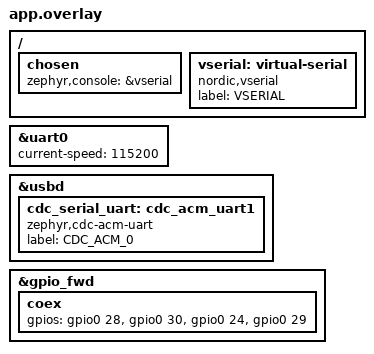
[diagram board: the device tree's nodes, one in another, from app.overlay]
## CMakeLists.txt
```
#
# Copyright (c) 2025 Mikko Jaakkola
#
# SPDX-License-Identifier: LicenseRef-Nordic-5-Clause
#

cmake_minimum_required(VERSION 3.20.5)
cmake_policy(SET CMP0057 NEW)

# Register the embedded80211 common link protocol library as an out-of-tree
# Zephyr module so its sources are compiled and linked into the image.
# Must be set before find_package(Zephyr) so the module is discovered during
# Zephyr's kernel-mode build configuration.
set(ZEPHYR_EXTRA_MODULES ${CMAKE_CURRENT_SOURCE_DIR}/../embedded80211)

# Rebalance the flash/SRAM partitions so the Wi-Fi co-processor appcore fits
# (see partitions.overlay.dts). Must be set before find_package(Zephyr): the
# variable is gathered during Zephyr package processing.
set(EXTRA_DTC_OVERLAY_FILE ${CMAKE_CURRENT_SOURCE_DIR}/partitions.overlay.dts)

find_package(Zephyr REQUIRED HINTS $ENV{ZEPHYR_BASE})

project(embedded80211_serial)

target_include_directories(app PUBLIC ${ZEPHYR_BASE}/subsys/net/ip)

target_sources(app PRIVATE
	src/main.c
)
```

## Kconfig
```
#
# Copyright (c) 2022 Nordic Semiconductor
#
# SPDX-License-Identifier: LicenseRef-Nordic-5-Clause
#

source "Kconfig.zephyr"
```

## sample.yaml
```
sample:
  description: Wi-Fi station sample application
  name: Wi-Fi station
tests:
  sample.nrf7002.sta:
    sysbuild: true
    build_only: true
    integration_platforms:
      - nrf7002dk/nrf5340/cpuapp
    platform_allow: nrf7002dk/nrf5340/cpuapp
    tags:
      - ci_build
      - sysbuild
      - ci_samples_wifi
  sample.nrf7002.sta.no_wifi_ready:
    sysbuild: true
    build_only: true
    extra_args: CONFIG_WIFI_READY_LIB=n
    integration_platforms:
      - nrf7002dk/nrf5340/cpuapp
    platform_allow: nrf7002dk/nrf5340/cpuapp
    tags:
      - ci_build
      - sysbuild
      - ci_samples_wifi
  sample.nrf7001.sta:
    sysbuild: true
    build_only: true
    integration_platforms:
      - nrf7002dk/nrf5340/cpuapp/nrf7001
    platform_allow: nrf7002dk/nrf5340/cpuapp/nrf7001
    tags:
      - ci_build
      - sysbuild
      - ci_samples_wifi
    skip: true
  sample.nrf7002_eks.sta:
    sysbuild: true
    build_only: true
    extra_args: SHIELD=nrf7002ek
    integration_platforms:
      - nrf5340dk/nrf5340/cpuapp
      - nrf52840dk/nrf52840
    platform_allow:
      - nrf5340dk/nrf5340/cpuapp
      - nrf52840dk/nrf52840
    extra_configs:
      - CONFIG_NET_TX_STACK_SIZE=3700
      - CONFIG_NET_RX_STACK_SIZE=3700
    tags:
      - ci_build
      - sysbuild
      - ci_samples_wifi
  sample.nrf7001_eks.sta:
    sysbuild: true
    build_only: true
    extra_args: SHIELD=nrf7002ek_nrf7001
    integration_platforms:
      - nrf5340dk/nrf5340/cpuapp
      - nrf52840dk/nrf52840
    platform_allow:
      - nrf5340dk/nrf5340/cpuapp
      - nrf52840dk/nrf52840
    extra_configs:
      - CONFIG_NET_TX_STACK_SIZE=3700
      - CONFIG_NET_RX_STACK_SIZE=3700
    tags:
      - ci_build
      - sysbuild
      - ci_samples_wifi
```

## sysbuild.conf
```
#
# Copyright (c) 2024 Nordic Semiconductor ASA
#
# SPDX-License-Identifier: LicenseRef-Nordic-5-Clause
#

SB_CONFIG_WIFI_NRF70=y

# Build the network core image (Nordic ipc_radio application) with the
# Bluetooth controller serialized to the application core over HCI IPC.
SB_CONFIG_NETCORE_IPC_RADIO_BT_HCI_IPC=y
```

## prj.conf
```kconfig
#
# Copyright (c) 2025 Mikko Jaakkola
#
#
CONFIG_WIFI=y
CONFIG_WIFI_NRF70=y

# WPA supplicant
CONFIG_WIFI_NM_WPA_SUPPLICANT=y
CONFIG_WIFI_READY_LIB=y
# Station-only, PSK/WPA2-CCMP: disable WPA3/SAE and legacy (WEP/TKIP/MD5/RC4)
# crypto to cut flash. This co-processor never uses SAE, WEP, or TKIP.
CONFIG_WIFI_NM_WPA_SUPPLICANT_WPA3_IMPLEMENTATION_EXT=n
CONFIG_WIFI_NM_WPA_SUPPLICANT_WPA3_IMPLEMENTATION_INT=n
CONFIG_WIFI_NM_WPA_SUPPLICANT_LEGACY_CRYPTO=n
CONFIG_WIFI_NM_WPA_SUPPLICANT_WEP=n
# Low power must be disabled for monitor-mode raw RX capture: with LPM the
# nRF7002 RPU puts the radio to sleep after ~10 ms idle, and in monitor mode
# there is no beacon/DTIM to wake it, so air frames are never captured.
# (Reference: nrf/tests/drivers/nrf_wifi/raw_tx_rx/prj.conf.)
# Note: this also disables CONFIG_NRF_WIFI_RPU_RECOVERY (depends on LPM).
CONFIG_NRF_WIFI_LOW_POWER=n
# Force a valid unicast station MAC. The default (CONFIG_WIFI_OTP_MAC_ADDRESS)
# makes nrf_wifi_get_mac_addr() write a dummy/garbage first octet with the
# multicast bit set (observed 03:06:f4:ce:36:00 on the bus); a DHCP server
# rejects DISCOVERs from such a source, so no OFFER ever returns. A fixed
# unicast MAC (bit0/bit1 of the first octet clear) fixes DHCP.
CONFIG_WIFI_FIXED_MAC_ADDRESS="62:34:56:78:9a:bc"

# Networking
CONFIG_NETWORKING=y
CONFIG_NET_SOCKETS=y
CONFIG_NET_IPV4=n
CONFIG_NET_UDP=n
CONFIG_NET_TCP=n
CONFIG_NET_DHCPV4=n

# Data proxy (co-processor) mode: the FMAC handles MAC filtering on the
# device MAC (00:00:00:00:00:00:01, which is also the host's MAC). Every L2
# frame the FMAC delivers is forwarded to the host over the bus via the
# nrf_wifi_if_rx_frm_hook (see wifi_data.c). Monitor/sniffer mode
# (PROMISC/RAW_DATA_RX) is NOT used here: it delivers every air frame
# (beacons, other clients) and breaks STA operation.
CONFIG_NRF70_RAW_DATA_TX=y
# Engineering: raw RX capture for broadcast-echo validation
CONFIG_WIFI_RAW_RX=y

CONFIG_NET_PKT_RX_COUNT=16
CONFIG_NET_PKT_TX_COUNT=8
CONFIG_NRF70_RX_NUM_BUFS=8

# Below section is the primary contributor to SRAM. Sized to fit the
# original 192 KB non-secure SRAM partition (was tuned for performance).
# Heap enlarged for wpa_supplicant (WPA state machine + EAPOL + ctrl iface
# need ~60 KB total; the 30 KB HEAP_MEM_POOL_ADD_SIZE_HOSTAP is added on
# top of HEAP_MEM_POOL_SIZE by the hostap module). Net bufs trimmed to
# compensate.
CONFIG_NET_BUF_RX_COUNT=8
CONFIG_NET_BUF_TX_COUNT=8
CONFIG_HEAP_MEM_POOL_SIZE=32000
CONFIG_HEAP_MEM_POOL_IGNORE_MIN=y
CONFIG_NRF_WIFI_CTRL_HEAP_SIZE=12000
CONFIG_NRF_WIFI_DATA_HEAP_SIZE=16000
CONFIG_NET_TC_TX_COUNT=1

#CONFIG_NET_IF_UNICAST_IPV4_ADDR_COUNT=1
CONFIG_NET_MAX_CONTEXTS=5
CONFIG_NET_CONTEXT_SYNC_RECV=y

CONFIG_INIT_STACKS=y

CONFIG_NET_L2_ETHERNET=y
CONFIG_NET_L2_ETHERNET_MGMT=y

CONFIG_NET_CONFIG_SETTINGS=y
CONFIG_NET_CONFIG_INIT_TIMEOUT=0

CONFIG_NET_SOCKETS_POLL_MAX=10

# Memories
CONFIG_MAIN_STACK_SIZE=5200
CONFIG_NET_TX_STACK_SIZE=4096
CONFIG_NET_RX_STACK_SIZE=4096
CONFIG_STA_SAMPLE_START_WIFI_THREAD_STACK_SIZE=5200

# Debugging
CONFIG_STACK_SENTINEL=y
# The FMAC RPC/RX path (incl. the embedded80211 RX hook) overflows the
# default RPMSG workqueue stack at boot when beacons are delivered.
CONFIG_IPC_SERVICE_BACKEND_RPMSG_WQ_STACK_SIZE=4096
# Main thread runs net_if / Wi-Fi init; 5200 bytes is fully consumed at boot.
CONFIG_MAIN_STACK_SIZE=6144
# The "wlan0" net-if management thread overflows at 4600 bytes during
# FMAC-init RPC handling; bump to 8192.
CONFIG_NET_MGMT_EVENT_STACK_SIZE=6144
CONFIG_SHELL_CMDS_RESIZE=n


# Kernel options
CONFIG_ENTROPY_GENERATOR=y

# Logging
CONFIG_LOG=y
CONFIG_LOG_BUFFER_SIZE=2048
# USB stack logging: WRN to keep boot log short so Wi-Fi connect logs fit
# in the 4 KB RTT ring (NO_BLOCK_SKIP drops everything once full).
CONFIG_USBD_LOG_LEVEL_WRN=y
CONFIG_UDC_DRIVER_LOG_LEVEL_WRN=y
CONFIG_USBD_CDC_ACM_LOG_LEVEL_WRN=y
# TEMP: connect-timeout diagnosis — WPA supplicant debug logs (level 1 = MSG_DEBUG).
# Remove once the -116 ETIMEDOUT root cause is found.
#CONFIG_WIFI_NM_WPA_SUPPLICANT_LOG_LEVEL_DBG=y
#CONFIG_WIFI_NM_WPA_SUPPLICANT_DEBUG_LEVEL=1
# Free flash for the debug logging above (not needed for basic STA connect).
#CONFIG_WIFI_NM_WPA_SUPPLICANT_ADVANCED_FEATURES=n

# Nanopb
CONFIG_NANOPB=y

# Bluetooth LE
# The controller is the nRF5340 on-chip SoftDevice Controller running on the
# network core (the ipc_radio netcore image, see Kconfig.sysbuild). The
# application core exposes a raw HCI channel to the host over the common
# link protocol (traffic type HCI, see src/bt_proxy.c).
CONFIG_BT=y
CONFIG_BT_HCI_RAW=y
CONFIG_MBOX=y
CONFIG_IPC_SERVICE=y

# Serial transport: the nRF5340 target USB connector (see app.overlay)
# exposes the common link protocol bus as USB CDC-ACM (CDC_ACM_0).
# The J-Link USB connector carries only SWD flash/debug and SEGGER RTT.

# Enable USB Subsystem (new USB device stack)
CONFIG_USB_DEVICE_STACK_NEXT=y
# The USB device controller (UDC NRF) thread handles CDC-ACM ISR events and
# overflows the default 512-byte stack at boot. Bump to 2048.
#CONFIG_UDC_NRF_THREAD_STACK_SIZE=4096

# Enable CDC ACM class for USB device stack next
CONFIG_USBD_CDC_ACM_CLASS=y

# Keep vserial for console, but don't proxy it to USB (prevents console
# output from corrupting the protocol data channel on CDC_ACM_0)
CONFIG_VSERIAL_ENABLE=y
CONFIG_SERIAL_MUX_VSERIAL_IFACE_UART=y
# Disable early console to prevent boot banner from corrupting CDC ACM data
CONFIG_EARLY_CONSOLE=n

# The USB device stack is initialized explicitly at boot by
# embedded80211/zephyr/device/serial/usbd_init.c (USBD_DEVICE_DEFINE +
# usbd_init()/usbd_enable()). It registers the first zephyr,cdc-acm-uart
# instance ("cdc_acm_0" = cdc_serial_uart, the multiplexer's USB backend
# bound by serial_usb.c). The VID/PID and descriptor strings are defined
# in usbd_init.c.

# Serial
CONFIG_SERIAL=y
 # Needed for USB CDC ACM. Aysynchronous serial port
# API would be better for all other serial ports.
CONFIG_UART_INTERRUPT_DRIVEN=y

# Enable RTT (Real-Time Transfer)
CONFIG_RTT_CONSOLE=y

# Choose SEGGER RTT as the backend (most common)
CONFIG_USE_SEGGER_RTT=y
CONFIG_SEGGER_RTT_BUFFER_SIZE_UP=4096
CONFIG_SEGGER_RTT_BUFFER_SIZE_DOWN=64
# Re-init the RTT control block unconditionally on every boot. The CB lives in
# a persistent section (not zeroed by startup), so the default strong-check
# mode reuses offsets left by the previous boot: the ring stays full of stale
# data and the skip-mode log writer drops everything new. Fresh ring per boot.
CONFIG_SEGGER_RTT_INIT_MODE_ALWAYS=y

# Workqueue.
CONFIG_SYSTEM_WORKQUEUE_STACK_SIZE=4096
CONFIG_SYSTEM_WORKQUEUE_PRIORITY=-1

# Enable events
CONFIG_EVENTS=y

# CRC32C for the link-protocol per-frame integrity feature (serial.c).
CONFIG_CRC=y
# The ARM MPU's default-deny background region blocks peripheral accesses
# (0x40000000+) that the SPU (configured by TF-M) is supposed to allow.
# The SPU handles all access control for the NS world; the ARM MPU is
# redundant and causes an MPU fault at boot when the NS image first
# touches a peripheral register.
CONFIG_ARM_MPU=n
```

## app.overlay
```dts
/*
 * Serial transport: the nRF5340 target USB connector (a second USB cable,
 * separate from the J-Link USB used for SWD flash/debug) exposes two USB
 * CDC-ACM ports (VID 0x2FE3):
 *
 *   CDC_ACM_0 (cdc_serial_uart):  common link protocol bus — the
 *                                 multiplexer's USB backend (serial_usb.c)
 *   CDC_ACM_1 (cdc_serial_uart2): spare port, not bound to a console
 *
 * The console is the vserial virtual UART (chosen below): by design the
 * Zephyr console has no physical pins, and console writes are dropped by
 * vserial's poll stub. Real logs flow over SEGGER RTT (SWD, J-Link cable).
 *
 * uart0 stays enabled as the multiplexer's UART backend (uart.c; default
 * CONFIG_SERIAL_MUX_IFACE_UART), but no protocol traffic is routed to it:
 * every traffic type defaults to the USB interface.
 */
&uart0 {
    status = "okay";
    current-speed = <115200>;
};

&usbd {
    cdc_serial_uart: cdc_acm_uart1 {
        compatible = "zephyr,cdc-acm-uart";
        label = "CDC_ACM_0";
    };
};
/* Forward the nRF7002 Wi-Fi PTA (coexistence) pins to the network core.
 * The network core drives them from the nrf_radio_coex node in its
 * devicetree (MPSL_CX_NRF700X), arbitrating RF access between the
 * nRF5340 Bluetooth radio and the nRF7002 Wi-Fi radio.
 */
&gpio_fwd {
    coex {
        gpios = <&gpio0 28 0>,  /* COEX_REQ */
                <&gpio0 30 0>,  /* COEX_STATUS0 */
                <&gpio0 24 0>,  /* COEX_GRANT */
                <&gpio0 29 0>;  /* SWCTRL1 */
    };
};

/ {
     chosen {
         /*
          * Console sink: the vserial virtual UART (no physical pins), by
          * design. Console writes are dropped by vserial's poll stub;
          * logs flow over SEGGER RTT (SWD, J-Link cable).
          */
         zephyr,console = &vserial;
     };

     vserial: virtual-serial {
         compatible = "nordic,vserial";
         status = "okay";
         label = "VSERIAL";
     };
};
```

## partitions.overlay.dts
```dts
/*
 * Copyright (c) 2025 Mikko Jaakkola
 *
 * SPDX-License-Identifier: LicenseRef-Nordic-5-Clause
 *
 * Project partition override for the nRF7002 DK non-secure appcore.
 *
 * The Wi-Fi co-processor appcore needs ~535 KB flash / ~201 KB SRAM, which
 * does not fit the default 192 KB non-secure partition (the nRF7002 radio
 * firmware + wpa_supplicant core alone are ~335 KB and are not trimmable).
 *
 * This overlay rebalances the 1 MB flash and 512 KB SRAM. This build has
 * BL2 disabled (BL2=FALSE), so the secure image is the first image and must
 * sit at 0x0 (the nRF5340 APP core always resets to 0x0). The default
 * mcuboot/BL2 partition at 0x0 is therefore removed and slot0 is moved to
 * 0x0:
 *
 *   Flash (1 MB):
 *     0x00000  slot0: S (128 KB) + NS (544 KB) = 672 KB
 *     0xA8000  free (was the 448 KB slot1 secondary; no in-place DFU here)
 *     0xF0000  PS (16 KB) / ITS (8 KB) / OTP (8 KB)
 *
 *   SRAM (512 KB):
 *     0x00000  sram0_s        (256 KB, secure)
 *     0x40000  sram0_ns_app   (208 KB)
 *     0x74000  sram0_shared   (48 KB, IPC)
 *
 * The NCS tfm_boards partition header derives the S/NS sizes from these DTS
 * nodes, so no upstream TF-M header is modified.
 */

&slot0_partition {
	reg = <0x00000000 0xA8000>;
	ranges = <0x0 0x0 0xA8000>;
};

&slot0_s_partition {
	reg = <0x00000000 0x20000>;
};

&slot0_ns_partition {
	reg = <0x00020000 0x88000>;
};

/* No BL2/MCUBoot in this build (BL2=FALSE): remove the 64 KB boot partition
 * at 0x0 so slot0 can start there. Also free the 448 KB secondary slot; this
 * build has no in-place DFU. */
&flash0 {
	partitions {
		/delete-node/ boot_partition;
		/delete-node/ slot1_partition;
	};
};

&sram0_ns_app {
	reg = <0x0 0x34000>;
};

&sram0_shared {
	reg = <0x74000 0xC000>;
};
```

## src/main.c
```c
/*
 * Copyright (c) 2022 Nordic Semiconductor ASA
 *
 * SPDX-License-Identifier: LicenseRef-Nordic-5-Clause
 */

/** @file
 * @brief WiFi station sample
 */

#include <zephyr/logging/log.h>
LOG_MODULE_REGISTER(embedded80211_serial, CONFIG_LOG_DEFAULT_LEVEL);

#include <zephyr/kernel.h>
#include <stdio.h>
#include <stdlib.h>
#include <zephyr/shell/shell.h>
#include <zephyr/sys/printk.h>
#include <zephyr/init.h>

#include <zephyr/net/net_if.h>
#include <zephyr/net/wifi_mgmt.h>
#include <zephyr/net/net_event.h>
#include <zephyr/drivers/gpio.h>

#ifdef CONFIG_WIFI_READY_LIB
#include <net/wifi_ready.h>
#endif /* CONFIG_WIFI_READY_LIB */

#if defined(CONFIG_BOARD_NRF7002DK_NRF7001_NRF5340_CPUAPP) || \
	defined(CONFIG_BOARD_NRF7002DK_NRF5340_CPUAPP)
#include <zephyr/drivers/wifi/nrf_wifi/bus/qspi_if.h>
#endif

#include "net_private.h"

#define WIFI_SHELL_MODULE "wifi"

#define WIFI_SHELL_MGMT_EVENTS (NET_EVENT_WIFI_CONNECT_RESULT |		\
				NET_EVENT_WIFI_DISCONNECT_RESULT)

#define MAX_SSID_LEN        32
#define STATUS_POLLING_MS   300

/* 1000 msec = 1 sec */
#define LED_SLEEP_TIME_MS   100

/* The devicetree node identifier for the "led0" alias. */
#define LED0_NODE DT_ALIAS(led0)
/*
 * A build error on this line means your board is unsupported.
 * See the sample documentation for information on how to fix this.
 */
static const struct gpio_dt_spec led = GPIO_DT_SPEC_GET(LED0_NODE, gpios);

static struct net_mgmt_event_callback wifi_shell_mgmt_cb;
static struct net_mgmt_event_callback net_shell_mgmt_cb;

#ifdef CONFIG_WIFI_READY_LIB
static K_SEM_DEFINE(wifi_ready_state_changed_sem, 0, 1);
static bool wifi_ready_status;
#endif /* CONFIG_WIFI_READY_LIB */

static struct {
	const struct shell *sh;
	union {
		struct {
			uint8_t connected	: 1;
			uint8_t connect_result	: 1;
			uint8_t disconnect_requested	: 1;
			uint8_t _unused		: 5;
		};
		uint8_t all;
	};
} context;

void toggle_led(void)
{
	int ret;

	if (!device_is_ready(led.port)) {
		LOG_ERR("LED device is not ready");
		return;
	}

	ret = gpio_pin_configure_dt(&led, GPIO_OUTPUT_ACTIVE);
	if (ret < 0) {
		LOG_ERR("Error %d: failed to configure LED pin", ret);
		return;
	}

	while (1) {
		if (context.connected) {
			gpio_pin_toggle_dt(&led);
			k_msleep(LED_SLEEP_TIME_MS);
		} else {
			gpio_pin_set_dt(&led, 0);
			k_msleep(LED_SLEEP_TIME_MS);
		}
	}
}

K_THREAD_DEFINE(led_thread_id, 1024, toggle_led, NULL, NULL, NULL,
		7, 0, 0);

static int cmd_wifi_status(void)
{
	struct net_if *iface = net_if_get_default();
	struct wifi_iface_status status = { 0 };

	if (net_mgmt(NET_REQUEST_WIFI_IFACE_STATUS, iface, &status,
				sizeof(struct wifi_iface_status))) {
		LOG_ERR("Status request failed");

		return -ENOEXEC;
	}

	/* The caller polls every STATUS_POLLING_MS; log only state changes so
	 * the log backend is not flooded with identical lines. */
	static bool have_last;
	static int last_state;

	if (have_last && status.state == last_state) {
		return 0;
	}
	have_last = true;
	last_state = status.state;

	LOG_INF("==================");
	LOG_INF("State: %s", wifi_state_txt(status.state));

	if (status.state >= WIFI_STATE_ASSOCIATED) {
		uint8_t mac_string_buf[sizeof("xx:xx:xx:xx:xx:xx")];

		LOG_INF("Interface Mode: %s",
		       wifi_mode_txt(status.iface_mode));
		LOG_INF("Link Mode: %s",
		       wifi_link_mode_txt(status.link_mode));
		LOG_INF("SSID: %.32s", status.ssid);
		LOG_INF("BSSID: %s",
		       net_sprint_ll_addr_buf(
				status.bssid, WIFI_MAC_ADDR_LEN,
				mac_string_buf, sizeof(mac_string_buf)));
		LOG_INF("Band: %s", wifi_band_txt(status.band));
		LOG_INF("Channel: %d", status.channel);
		LOG_INF("Security: %s", wifi_security_txt(status.security));
		LOG_INF("MFP: %s", wifi_mfp_txt(status.mfp));
		LOG_INF("RSSI: %d", status.rssi);
	}
	return 0;
}

static void handle_wifi_connect_result(struct net_mgmt_event_callback *cb)
{
	const struct wifi_status *status =
		(const struct wifi_status *) cb->info;

	if (context.connected) {
		return;
	}

	if (status->status) {
		LOG_ERR("Connection failed (%d)", status->status);
	} else {
		LOG_INF("Connected");
		context.connected = true;
	}

	context.connect_result = true;
}

static void handle_wifi_disconnect_result(struct net_mgmt_event_callback *cb)
{
	const struct wifi_status *status =
		(const struct wifi_status *) cb->info;

	if (!context.connected) {
		return;
	}

	if (context.disconnect_requested) {
		LOG_INF("Disconnection request %s (%d)",
			 status->status ? "failed" : "done",
					status->status);
		context.disconnect_requested = false;
	} else {
		LOG_INF("Received Disconnected");
		context.connected = false;
	}

	cmd_wifi_status();
}

static void wifi_mgmt_event_handler(struct net_mgmt_event_callback *cb,
				     uint64_t mgmt_event, struct net_if *iface)
{
	switch (mgmt_event) {
	case NET_EVENT_WIFI_CONNECT_RESULT:
		handle_wifi_connect_result(cb);
		break;
	case NET_EVENT_WIFI_DISCONNECT_RESULT:
		handle_wifi_disconnect_result(cb);
		break;
	default:
		break;
	}
}

static void net_mgmt_event_handler(struct net_mgmt_event_callback *cb,
				    uint64_t mgmt_event, struct net_if *iface)
{
	switch (mgmt_event) {
	case NET_EVENT_IPV4_DHCP_BOUND:
		//print_dhcp_ip(cb);
		break;
	default:
		break;
	}
}

int bytes_from_str(const char *str, uint8_t *bytes, size_t bytes_len)
{
	size_t i;
	char byte_str[3];

	if (strlen(str) != bytes_len * 2) {
		LOG_ERR("Invalid string length: %zu (expected: %d)\n",
			strlen(str), bytes_len * 2);
		return -EINVAL;
	}

	for (i = 0; i < bytes_len; i++) {
		memcpy(byte_str, str + i * 2, 2);
		byte_str[2] = '\0';
		bytes[i] = strtol(byte_str, NULL, 16);
	}

	return 0;
}

int start_app(void)
{
#if defined(CONFIG_BOARD_NRF7002DK_NRF7001_NRF5340_CPUAPP) || \
	defined(CONFIG_BOARD_NRF7002DK_NRF5340_CPUAPP)
	if (strlen(CONFIG_NRF70_QSPI_ENCRYPTION_KEY)) {
		int ret;
		char key[QSPI_KEY_LEN_BYTES];

		ret = bytes_from_str(CONFIG_NRF70_QSPI_ENCRYPTION_KEY, key, sizeof(key));
		if (ret) {
			LOG_ERR("Failed to parse encryption key: %d\n", ret);
			return 0;
		}

		LOG_DBG("QSPI Encryption key: ");
		for (int i = 0; i < QSPI_KEY_LEN_BYTES; i++) {
			LOG_DBG("%02x", key[i]);
		}
		LOG_DBG("\n");

		ret = qspi_enable_encryption(key);
		if (ret) {
			LOG_ERR("Failed to enable encryption: %d\n", ret);
			return 0;
		}
		LOG_INF("QSPI Encryption enabled");
	} else {
		LOG_INF("QSPI Encryption disabled");
	}
#endif /* CONFIG_BOARD_NRF700XDK_NRF5340 */

	while (1) {
#ifdef CONFIG_WIFI_READY_LIB
		int ret;

		LOG_INF("Waiting for Wi-Fi to be ready");
		ret = k_sem_take(&wifi_ready_state_changed_sem, K_FOREVER);
		if (ret) {
			LOG_ERR("Failed to take semaphore: %d", ret);
			return ret;
		}

		if (!wifi_ready_status) {
			LOG_INF("Wi-Fi is not ready");
			/* Perform any cleanup and stop using Wi-Fi and wait for
			 * Wi-Fi to be ready
			 */
			continue;
		}
#endif /* CONFIG_WIFI_READY_LIB */
		/* Proxy mode: the host drives Wi-Fi over the serial link
		 * (scan / connect / AP via cli_test). Do not auto-connect
		 * here — a boot-time connect would race the host's
		 * requests and can leave the driver stuck in SCANNING. */
		LOG_INF("Wi-Fi ready — proxy mode (host-driven over serial)");
		k_sleep(K_FOREVER);
	}

	return 0;
}

#ifdef CONFIG_WIFI_READY_LIB
void start_wifi_thread(void);
#define THREAD_PRIORITY K_PRIO_COOP(CONFIG_NUM_COOP_PRIORITIES - 1)
K_THREAD_DEFINE(start_wifi_thread_id, CONFIG_STA_SAMPLE_START_WIFI_THREAD_STACK_SIZE,
		start_wifi_thread, NULL, NULL, NULL,
		THREAD_PRIORITY, 0, -1);

void start_wifi_thread(void)
{
	start_app();
}

void wifi_ready_cb(bool wifi_ready)
{
	LOG_DBG("Is Wi-Fi ready?: %s", wifi_ready ? "yes" : "no");
	wifi_ready_status = wifi_ready;
	k_sem_give(&wifi_ready_state_changed_sem);
}
#endif /* CONFIG_WIFI_READY_LIB */

void net_mgmt_callback_init(void)
{
	memset(&context, 0, sizeof(context));

	net_mgmt_init_event_callback(&wifi_shell_mgmt_cb,
				     wifi_mgmt_event_handler,
				     WIFI_SHELL_MGMT_EVENTS);

	net_mgmt_add_event_callback(&wifi_shell_mgmt_cb);

	net_mgmt_init_event_callback(&net_shell_mgmt_cb,
				     net_mgmt_event_handler,
				     NET_EVENT_IPV4_DHCP_BOUND);

	net_mgmt_add_event_callback(&net_shell_mgmt_cb);

	LOG_INF("Starting %s with CPU frequency: %d MHz", CONFIG_BOARD, SystemCoreClock/MHZ(1));
	k_sleep(K_SECONDS(1));
}

#ifdef CONFIG_WIFI_READY_LIB
static int register_wifi_ready(void)
{
	int ret = 0;
	wifi_ready_callback_t cb;
	struct net_if *iface = net_if_get_first_wifi();

	if (!iface) {
		LOG_ERR("Failed to get Wi-Fi interface");
		return -1;
	}

	cb.wifi_ready_cb = wifi_ready_cb;

	LOG_DBG("Registering Wi-Fi ready callbacks");
	ret = register_wifi_ready_callback(cb, iface);
	if (ret) {
		LOG_ERR("Failed to register Wi-Fi ready callbacks %s", strerror(ret));
		return ret;
	}

	return ret;
}
#endif /* CONFIG_WIFI_READY_LIB */

int main(void)
{
	int ret = 0;

	LOG_INF("Starting %s with CPU frequency: %d MHz", CONFIG_BOARD, SystemCoreClock/MHZ(1));

	net_mgmt_callback_init();

#ifdef CONFIG_WIFI_READY_LIB
	ret = register_wifi_ready();
	if (ret) {
		return ret;
	}
	k_thread_start(start_wifi_thread_id);
#else
	start_app();
#endif /* CONFIG_WIFI_READY_LIB */
	return ret;
}
```
